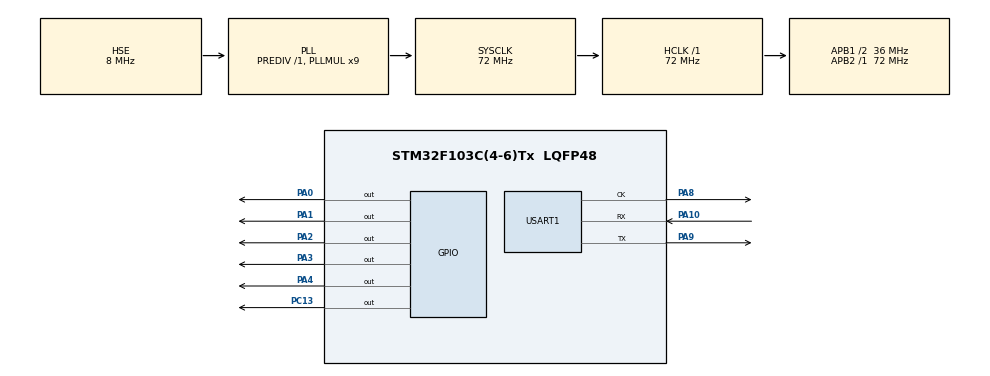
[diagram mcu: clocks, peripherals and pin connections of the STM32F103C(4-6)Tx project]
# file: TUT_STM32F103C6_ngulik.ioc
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Mcu.Family=STM32F1
Mcu.Name=STM32F103C(4-6)Tx
Mcu.Package=LQFP48
NVIC.PriorityGroup=NVIC_PRIORITYGROUP_4
PA0-WKUP.Signal=GPIO_Output
PA1.Signal=GPIO_Output
PA10.Mode=Synchronous
PA10.Signal=USART1_RX
PA13.Mode=Serial_Wire
PA13.Signal=SYS_JTMS-SWDIO
PA14.Mode=Serial_Wire
PA14.Signal=SYS_JTCK-SWCLK
PA2.Signal=GPIO_Output
PA3.Signal=GPIO_Output
PA4.Signal=GPIO_Output
PA8.Mode=Synchronous
PA8.Signal=USART1_CK
PA9.Mode=Synchronous
PA9.Signal=USART1_TX
PC13-TAMPER-RTC.Signal=GPIO_Output
PD0-OSC_IN.Mode=HSE-External-Oscillator
PD0-OSC_IN.Signal=RCC_OSC_IN
PD1-OSC_OUT.Mode=HSE-External-Oscillator
PD1-OSC_OUT.Signal=RCC_OSC_OUT
ProjectManager.HeapSize=0x200
ProjectManager.StackSize=0x400
ProjectManager.TargetToolchain=Makefile
RCC.AHBFreq_Value=72000000
RCC.APB1CLKDivider=RCC_HCLK_DIV2
RCC.APB1Freq_Value=36000000
RCC.APB1TimFreq_Value=72000000
RCC.APB2Freq_Value=72000000
RCC.APB2TimFreq_Value=72000000
RCC.HCLKFreq_Value=72000000
RCC.PLLMUL=RCC_PLL_MUL9
RCC.PLLSourceVirtual=RCC_PLLSOURCE_HSE
RCC.SYSCLKFreq_VALUE=72000000
RCC.SYSCLKSource=RCC_SYSCLKSOURCE_PLLCLK
RCC.USBFreq_Value=72000000
USART1.VirtualMode=VM_SYNC
board=custom

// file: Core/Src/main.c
/* USER CODE BEGIN Header */
/**
  ******************************************************************************
  * @file           : main.c
  * @brief          : Main program body
  ******************************************************************************
  * @attention
  *
  * Copyright (c) 2022 STMicroelectronics.
  * All rights reserved.
  *
  * This software is licensed under terms that can be found in the LICENSE file
  * in the root directory of this software component.
  * If no LICENSE file comes with this software, it is provided AS-IS.
  *
  ******************************************************************************
  */
/* USER CODE END Header */
#include "main.h"

/* USER CODE BEGIN Includes */
#define ADC_BASE_ADDR       0x40012400UL
#define ADC_CR1_REG_OFFSET  0x04UL
#define ADC_CR1_REG_ADDR    (ADC_BASE_ADDR + ADC_CR1_REG_OFFSET)
#define RCC_BASE_ADDR       0x40002800UL
#define RCC_APB2_ENR_OFFSET 0x18UL
#define RCC_APB2_ENR_ADRR   (RCC_BASE_ADDR + RCC_APB2_ENR_OFFSET)

/* USER CODE END Includes */

 USART_HandleTypeDef husart1;

void SystemClock_Config(void);
static void MX_GPIO_Init(void);
static void MX_USART1_Init(void);

/* USER CODE BEGIN 0 */
void USARTSend(char *pucBuffer, unsigned long ulCount){
  while(ulCount--){

  }
}
/* USER CODE END 0 */

int main(void)
{

  /* MCU Configuration--------------------------------------------------------*/

  /* Reset of all peripherals, Initializes the Flash interface and the Systick. */
  HAL_Init();

  /* Configure the system clock */
  SystemClock_Config();

  /* Initialize all configured peripherals */
  MX_GPIO_Init();
  MX_USART1_Init();
  /* USER CODE BEGIN 2 */
  uint32_t *pAdcCr1Reg = (uint32_t*) ADC_CR1_REG_ADDR;
  uint32_t *pRccApb2Enr = (uint32_t*) RCC_APB2_ENR_ADRR;

  /* USER CODE END 2 */

  /* Infinite loop */
  while (1)
  {

    /* USER CODE BEGIN 3 */

  //1. enable peripheral clock untuk ADC1
  *pRccApb2Enr |= (1 << 8);
  //2. modifikasi ADC CR1 register
  *pAdcCr1Reg |= (1 << 8);
    HAL_GPIO_TogglePin(GPIOC, GPIO_PIN_13);
    HAL_Delay(2000);
    // HAL_GPIO_TogglePin(GPIOC, GPIO_PIN_13);
    // HAL_Delay(100);
  }
  /* USER CODE END 3 */
}

void SystemClock_Config(void)
{
  RCC_OscInitTypeDef RCC_OscInitStruct = {0};
  RCC_ClkInitTypeDef RCC_ClkInitStruct = {0};

  /** Initializes the RCC Oscillators according to the specified parameters
  * in the RCC_OscInitTypeDef structure.
  */
  RCC_OscInitStruct.OscillatorType = RCC_OSCILLATORTYPE_HSE;
  RCC_OscInitStruct.HSEState = RCC_HSE_ON;
  RCC_OscInitStruct.HSEPredivValue = RCC_HSE_PREDIV_DIV1;
  RCC_OscInitStruct.HSIState = RCC_HSI_ON;
  RCC_OscInitStruct.PLL.PLLState = RCC_PLL_ON;
  RCC_OscInitStruct.PLL.PLLSource = RCC_PLLSOURCE_HSE;
  RCC_OscInitStruct.PLL.PLLMUL = RCC_PLL_MUL9;
  if (HAL_RCC_OscConfig(&RCC_OscInitStruct) != HAL_OK)
  {
    Error_Handler();
  }

  /** Initializes the CPU, AHB and APB buses clocks
  */
  RCC_ClkInitStruct.ClockType = RCC_CLOCKTYPE_HCLK|RCC_CLOCKTYPE_SYSCLK
                              |RCC_CLOCKTYPE_PCLK1|RCC_CLOCKTYPE_PCLK2;
  RCC_ClkInitStruct.SYSCLKSource = RCC_SYSCLKSOURCE_PLLCLK;
  RCC_ClkInitStruct.AHBCLKDivider = RCC_SYSCLK_DIV1;
  RCC_ClkInitStruct.APB1CLKDivider = RCC_HCLK_DIV2;
  RCC_ClkInitStruct.APB2CLKDivider = RCC_HCLK_DIV1;

  if (HAL_RCC_ClockConfig(&RCC_ClkInitStruct, FLASH_LATENCY_2) != HAL_OK)
  {
    Error_Handler();
  }
}

static void MX_USART1_Init(void)
{

  husart1.Instance = USART1;
  husart1.Init.BaudRate = 115200;
  husart1.Init.WordLength = USART_WORDLENGTH_8B;
  husart1.Init.StopBits = USART_STOPBITS_1;
  husart1.Init.Parity = USART_PARITY_NONE;
  husart1.Init.Mode = USART_MODE_TX_RX;
  husart1.Init.CLKPolarity = USART_POLARITY_LOW;
  husart1.Init.CLKPhase = USART_PHASE_1EDGE;
  husart1.Init.CLKLastBit = USART_LASTBIT_DISABLE;
  if (HAL_USART_Init(&husart1) != HAL_OK)
  {
    Error_Handler();
  }

}

static void MX_GPIO_Init(void)
{
  GPIO_InitTypeDef GPIO_InitStruct = {0};

  /* GPIO Ports Clock Enable */
  __HAL_RCC_GPIOC_CLK_ENABLE();
  __HAL_RCC_GPIOD_CLK_ENABLE();
  __HAL_RCC_GPIOA_CLK_ENABLE();

  /*Configure GPIO pin Output Level */
  HAL_GPIO_WritePin(GPIOC, GPIO_PIN_13, GPIO_PIN_RESET);

  /*Configure GPIO pin Output Level */
  HAL_GPIO_WritePin(GPIOA, GPIO_PIN_0|GPIO_PIN_1|GPIO_PIN_2|GPIO_PIN_3
                          |GPIO_PIN_4, GPIO_PIN_RESET);

  /*Configure GPIO pin : PC13 */
  GPIO_InitStruct.Pin = GPIO_PIN_13;
  GPIO_InitStruct.Mode = GPIO_MODE_OUTPUT_PP;
  GPIO_InitStruct.Pull = GPIO_NOPULL;
  GPIO_InitStruct.Speed = GPIO_SPEED_FREQ_LOW;
  HAL_GPIO_Init(GPIOC, &GPIO_InitStruct);

  /*Configure GPIO pins : PA0 PA1 PA2 PA3
                           PA4 */
  GPIO_InitStruct.Pin = GPIO_PIN_0|GPIO_PIN_1|GPIO_PIN_2|GPIO_PIN_3
                          |GPIO_PIN_4;
  GPIO_InitStruct.Mode = GPIO_MODE_OUTPUT_PP;
  GPIO_InitStruct.Pull = GPIO_NOPULL;
  GPIO_InitStruct.Speed = GPIO_SPEED_FREQ_LOW;
  HAL_GPIO_Init(GPIOA, &GPIO_InitStruct);

}

void Error_Handler(void)
{
  __disable_irq();
  while (1)
  {
  }
}
